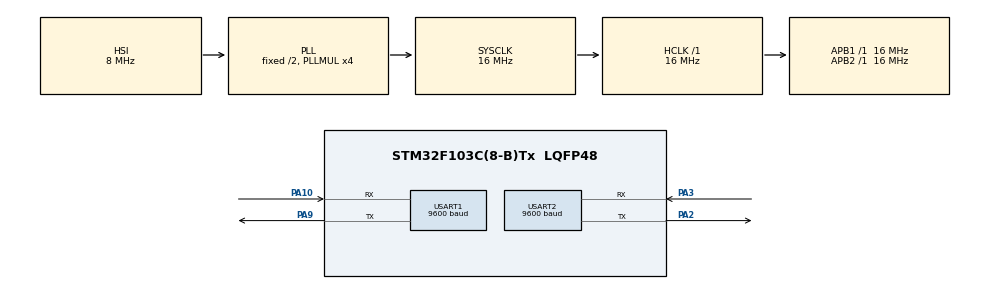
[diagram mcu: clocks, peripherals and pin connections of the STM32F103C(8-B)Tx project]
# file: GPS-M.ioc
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Dma.Request0=USART2_RX
Dma.Request1=USART1_RX
Dma.Request2=USART1_TX
Dma.USART1_RX.1.Direction=DMA_PERIPH_TO_MEMORY
Dma.USART1_RX.1.Instance=DMA1_Channel5
Dma.USART1_RX.1.MemDataAlignment=DMA_MDATAALIGN_BYTE
Dma.USART1_RX.1.MemInc=DMA_MINC_ENABLE
Dma.USART1_RX.1.Mode=DMA_NORMAL
Dma.USART1_RX.1.PeriphDataAlignment=DMA_PDATAALIGN_BYTE
Dma.USART1_RX.1.PeriphInc=DMA_PINC_DISABLE
Dma.USART1_RX.1.Priority=DMA_PRIORITY_LOW
Dma.USART1_TX.2.Direction=DMA_MEMORY_TO_PERIPH
Dma.USART1_TX.2.Instance=DMA1_Channel4
Dma.USART1_TX.2.MemDataAlignment=DMA_MDATAALIGN_BYTE
Dma.USART1_TX.2.MemInc=DMA_MINC_ENABLE
Dma.USART1_TX.2.Mode=DMA_NORMAL
Dma.USART1_TX.2.PeriphDataAlignment=DMA_PDATAALIGN_BYTE
Dma.USART1_TX.2.PeriphInc=DMA_PINC_DISABLE
Dma.USART1_TX.2.Priority=DMA_PRIORITY_LOW
Dma.USART2_RX.0.Direction=DMA_PERIPH_TO_MEMORY
Dma.USART2_RX.0.Instance=DMA1_Channel6
Dma.USART2_RX.0.MemDataAlignment=DMA_MDATAALIGN_BYTE
Dma.USART2_RX.0.MemInc=DMA_MINC_ENABLE
Dma.USART2_RX.0.Mode=DMA_NORMAL
Dma.USART2_RX.0.PeriphDataAlignment=DMA_PDATAALIGN_BYTE
Dma.USART2_RX.0.PeriphInc=DMA_PINC_DISABLE
Dma.USART2_RX.0.Priority=DMA_PRIORITY_LOW
Mcu.Family=STM32F1
Mcu.Name=STM32F103C(8-B)Tx
Mcu.Package=LQFP48
NVIC.DMA1_Channel4_IRQn=true\:0\:0\:false\:false\:true\:false\:true
NVIC.DMA1_Channel5_IRQn=true\:0\:0\:false\:false\:true\:false\:true
NVIC.DMA1_Channel6_IRQn=true\:0\:0\:false\:false\:true\:false\:true
NVIC.PriorityGroup=NVIC_PRIORITYGROUP_4
NVIC.USART1_IRQn=true\:0\:0\:false\:false\:true\:true\:true
NVIC.USART2_IRQn=true\:0\:0\:false\:false\:true\:true\:true
PA10.Mode=Asynchronous
PA10.Signal=USART1_RX
PA13.Mode=Serial_Wire
PA13.Signal=SYS_JTMS-SWDIO
PA14.Mode=Serial_Wire
PA14.Signal=SYS_JTCK-SWCLK
PA2.Mode=Asynchronous
PA2.Signal=USART2_TX
PA3.Mode=Asynchronous
PA3.Signal=USART2_RX
PA9.Mode=Asynchronous
PA9.Signal=USART1_TX
ProjectManager.HeapSize=0x200
ProjectManager.StackSize=0x400
ProjectManager.TargetToolchain=TrueSTUDIO
RCC.AHBFreq_Value=16000000
RCC.APB1Freq_Value=16000000
RCC.APB1TimFreq_Value=16000000
RCC.APB2Freq_Value=16000000
RCC.APB2TimFreq_Value=16000000
RCC.HCLKFreq_Value=16000000
RCC.PLLMUL=RCC_PLL_MUL4
RCC.SYSCLKFreq_VALUE=16000000
RCC.SYSCLKSource=RCC_SYSCLKSOURCE_PLLCLK
RCC.USBFreq_Value=16000000
USART1.BaudRate=9600
USART1.VirtualMode=VM_ASYNC
USART2.BaudRate=9600
USART2.VirtualMode=VM_ASYNC
board=custom

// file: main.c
/* USER CODE BEGIN Header */
/**
 ******************************************************************************
 * @file           : main.c
 * @brief          : Main program body
 ******************************************************************************
 * @attention
 *
 * <h2><center>&copy; Copyright (c) 2020 STMicroelectronics.
 * All rights reserved.</center></h2>
 *
 * This software component is licensed by ST under BSD 3-Clause license,
 * the "License"; You may not use this file except in compliance with the
 * License. You may obtain a copy of the License at:
 *                        opensource.org/licenses/BSD-3-Clause
 *
 ******************************************************************************
 */
/* USER CODE END Header */

#include "main.h"

/* USER CODE BEGIN Includes */
#include "GPS-M.h"
/* USER CODE END Includes */

UART_HandleTypeDef huart1;
UART_HandleTypeDef huart2;
DMA_HandleTypeDef hdma_usart1_rx;
DMA_HandleTypeDef hdma_usart1_tx;
DMA_HandleTypeDef hdma_usart2_rx;

void SystemClock_Config(void);
static void MX_GPIO_Init(void);
static void MX_DMA_Init(void);
static void MX_USART1_UART_Init(void);
static void MX_USART2_UART_Init(void);

#include <math.h>
int main(void) {

	/* MCU Configuration--------------------------------------------------------*/

	/* Reset of all peripherals, Initializes the Flash interface and the Systick. */
	HAL_Init();

	/* Configure the system clock */
	SystemClock_Config();

	/* Initialize all configured peripherals */
	MX_GPIO_Init();
	MX_DMA_Init();
	MX_USART1_UART_Init();
	MX_USART2_UART_Init();
	GPSInit();									//<----------
	uint8_t M = 1;								//<----------
	HAL_UART_Transmit(&huart1, &M, 1, 10);		//<----------
	/* Infinite loop */
	while (1) {
		float X = GPSLocationN(), Y = GPSLocationE();	//<----------

		// for print in uart
		uint32_t x = X * pow(10, 6), y = Y * pow(10, 6);

		uint8_t T[4];
		for (int i = 0; i < 4; i++)
			T[i] = (uint8_t) ((x >> (8 * i)) & 0XFF);
		HAL_UART_Transmit(&huart1, T, 4, 100);

		for (int i = 0; i < 4; i++)
			T[i] = (uint8_t) ((y >> (8 * i)) & 0XFF);
		HAL_UART_Transmit(&huart1, T, 4, 100);
		// end for print in uart

		HAL_Delay(10000);
	}
}

void SystemClock_Config(void) {
	RCC_OscInitTypeDef RCC_OscInitStruct = { 0 };
	RCC_ClkInitTypeDef RCC_ClkInitStruct = { 0 };

	/** Initializes the CPU, AHB and APB busses clocks
	 */
	RCC_OscInitStruct.OscillatorType = RCC_OSCILLATORTYPE_HSI;
	RCC_OscInitStruct.HSIState = RCC_HSI_ON;
	RCC_OscInitStruct.HSICalibrationValue = RCC_HSICALIBRATION_DEFAULT;
	RCC_OscInitStruct.PLL.PLLState = RCC_PLL_ON;
	RCC_OscInitStruct.PLL.PLLSource = RCC_PLLSOURCE_HSI_DIV2;
	RCC_OscInitStruct.PLL.PLLMUL = RCC_PLL_MUL4;
	if (HAL_RCC_OscConfig(&RCC_OscInitStruct) != HAL_OK) {
		Error_Handler();
	}
	/** Initializes the CPU, AHB and APB busses clocks
	 */
	RCC_ClkInitStruct.ClockType = RCC_CLOCKTYPE_HCLK | RCC_CLOCKTYPE_SYSCLK
			| RCC_CLOCKTYPE_PCLK1 | RCC_CLOCKTYPE_PCLK2;
	RCC_ClkInitStruct.SYSCLKSource = RCC_SYSCLKSOURCE_PLLCLK;
	RCC_ClkInitStruct.AHBCLKDivider = RCC_SYSCLK_DIV1;
	RCC_ClkInitStruct.APB1CLKDivider = RCC_HCLK_DIV1;
	RCC_ClkInitStruct.APB2CLKDivider = RCC_HCLK_DIV1;

	if (HAL_RCC_ClockConfig(&RCC_ClkInitStruct, FLASH_LATENCY_0) != HAL_OK) {
		Error_Handler();
	}
}

static void MX_USART1_UART_Init(void) {

	huart1.Instance = USART1;
	huart1.Init.BaudRate = 9600;
	huart1.Init.WordLength = UART_WORDLENGTH_8B;
	huart1.Init.StopBits = UART_STOPBITS_1;
	huart1.Init.Parity = UART_PARITY_NONE;
	huart1.Init.Mode = UART_MODE_TX_RX;
	huart1.Init.HwFlowCtl = UART_HWCONTROL_NONE;
	huart1.Init.OverSampling = UART_OVERSAMPLING_16;
	if (HAL_UART_Init(&huart1) != HAL_OK) {
		Error_Handler();
	}

}

static void MX_USART2_UART_Init(void) {

	huart2.Instance = USART2;
	huart2.Init.BaudRate = 9600;
	huart2.Init.WordLength = UART_WORDLENGTH_8B;
	huart2.Init.StopBits = UART_STOPBITS_1;
	huart2.Init.Parity = UART_PARITY_NONE;
	huart2.Init.Mode = UART_MODE_TX_RX;
	huart2.Init.HwFlowCtl = UART_HWCONTROL_NONE;
	huart2.Init.OverSampling = UART_OVERSAMPLING_16;
	if (HAL_UART_Init(&huart2) != HAL_OK) {
		Error_Handler();
	}

}

static void MX_DMA_Init(void) {

	/* DMA controller clock enable */
	__HAL_RCC_DMA1_CLK_ENABLE()
	;

	/* DMA interrupt init */
	/* DMA1_Channel4_IRQn interrupt configuration */
	HAL_NVIC_SetPriority(DMA1_Channel4_IRQn, 0, 0);
	HAL_NVIC_EnableIRQ(DMA1_Channel4_IRQn);
	/* DMA1_Channel5_IRQn interrupt configuration */
	HAL_NVIC_SetPriority(DMA1_Channel5_IRQn, 0, 0);
	HAL_NVIC_EnableIRQ(DMA1_Channel5_IRQn);
	/* DMA1_Channel6_IRQn interrupt configuration */
	HAL_NVIC_SetPriority(DMA1_Channel6_IRQn, 0, 0);
	HAL_NVIC_EnableIRQ(DMA1_Channel6_IRQn);

}

static void MX_GPIO_Init(void) {

	/* GPIO Ports Clock Enable */
	__HAL_RCC_GPIOA_CLK_ENABLE()
	;

}

void Error_Handler(void) {
}

/************************ (C) COPYRIGHT STMicroelectronics *****END OF FILE****/
